# PIC32MX695F512L register map
Registers are 32-bit, access not given, reset 0x0 unless marked. A register's access mark holds for its fields unless they carry their own. Offsets are from the block's base; [hi:lo] are bit positions; {n}, {i} and the like mark numbered series; 'fields as' and 'values as' point back to an identical list.

## INT — INT peripheral
Base 0xBF881000
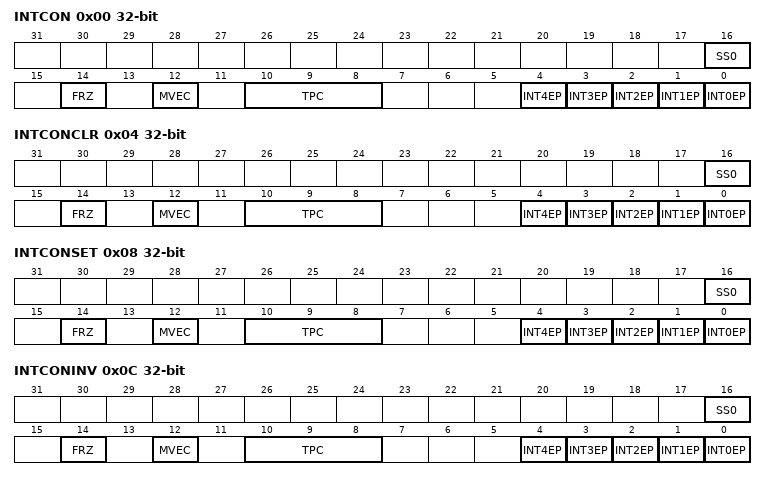
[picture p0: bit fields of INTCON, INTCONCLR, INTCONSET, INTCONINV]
0x00 INTCON
  [16] SS0, [14] FRZ, [12] MVEC, [10:8] TPC, [n] INT{n}EP (n=0..4)
0x04 INTCONCLR
  [16] SS0, [14] FRZ, [12] MVEC, [10:8] TPC, [n] INT{n}EP (n=0..4)
0x08 INTCONSET
  [16] SS0, [14] FRZ, [12] MVEC, [10:8] TPC, [n] INT{n}EP (n=0..4)
0x0C INTCONINV
  [16] SS0, [14] FRZ, [12] MVEC, [10:8] TPC, [n] INT{n}EP (n=0..4)
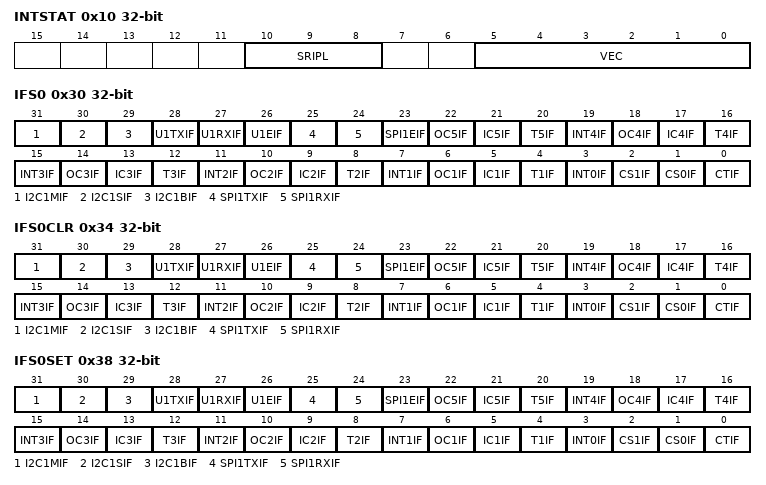
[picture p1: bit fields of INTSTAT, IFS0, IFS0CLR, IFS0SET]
0x10 INTSTAT
  [10:8] SRIPL, [5:0] VEC
0x20 IPTMR
0x24 IPTMRCLR
  [31:0] IPTMR
0x28 IPTMRSET
  [31:0] IPTMR
0x2C IPTMRINV
  [31:0] IPTMR
0x30 IFS0
  [31] I2C1MIF, [30] I2C1SIF, [29] I2C1BIF, [28] U1TXIF, [27] U1RXIF, [26] U1EIF, [25] SPI1TXIF, [24] SPI1RXIF, [23] SPI1EIF, [4n+2] OC{n}IF (n=1..5), [4n+1] IC{n}IF (n=1..5), [4n] T{n}IF (n=1..5), [4n+3] INT{n}IF (n=0..4), [2] CS1IF, [1] CS0IF, [0] CTIF
0x34 IFS0CLR
  fields as IFS0
0x38 IFS0SET
  fields as IFS0
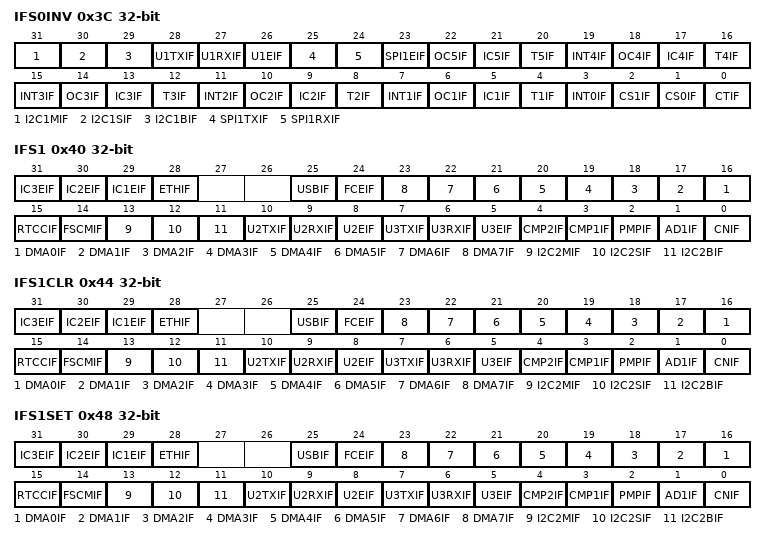
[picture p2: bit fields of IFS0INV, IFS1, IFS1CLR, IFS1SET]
0x3C IFS0INV
  fields as IFS0
0x40 IFS1
  [31] IC3EIF, [30] IC2EIF, [29] IC1EIF, [28] ETHIF, [25] USBIF, [24] FCEIF, [n+16] DMA{n}IF (n=0..7), [15] RTCCIF, [14] FSCMIF, [13] I2C2MIF, [12] I2C2SIF, [11] I2C2BIF, [10] U2TXIF, [9] U2RXIF, [8] U2EIF, [7] U3TXIF, [6] U3RXIF, [5] U3EIF, [4] CMP2IF, [3] CMP1IF, [2] PMPIF, [1] AD1IF, [0] CNIF
0x44 IFS1CLR
  fields as IFS1
0x48 IFS1SET
  fields as IFS1
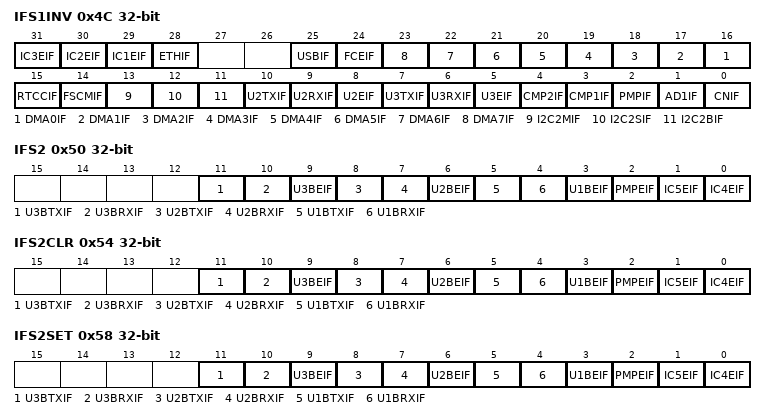
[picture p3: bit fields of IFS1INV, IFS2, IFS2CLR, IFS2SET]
0x4C IFS1INV
  fields as IFS1
0x50 IFS2
  [11] U3BTXIF, [10] U3BRXIF, [9] U3BEIF, [8] U2BTXIF, [7] U2BRXIF, [6] U2BEIF, [5] U1BTXIF, [4] U1BRXIF, [3] U1BEIF, [2] PMPEIF, [1] IC5EIF, [0] IC4EIF
0x54 IFS2CLR
  fields as IFS2
0x58 IFS2SET
  fields as IFS2
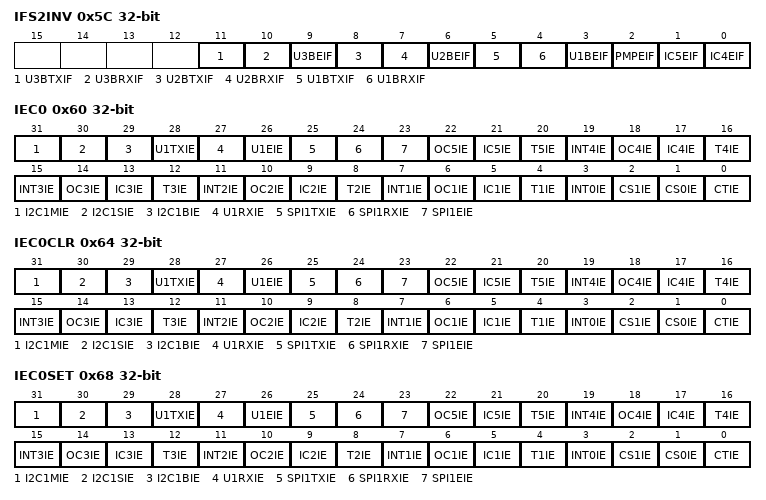
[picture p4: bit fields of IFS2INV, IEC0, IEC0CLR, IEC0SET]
0x5C IFS2INV
  fields as IFS2
0x60 IEC0
  [31] I2C1MIE, [30] I2C1SIE, [29] I2C1BIE, [28] U1TXIE, [27] U1RXIE, [26] U1EIE, [25] SPI1TXIE, [24] SPI1RXIE, [23] SPI1EIE, [4n+2] OC{n}IE (n=1..5), [4n+1] IC{n}IE (n=1..5), [4n] T{n}IE (n=1..5), [4n+3] INT{n}IE (n=0..4), [2] CS1IE, [1] CS0IE, [0] CTIE
0x64 IEC0CLR
  fields as IEC0
0x68 IEC0SET
  fields as IEC0
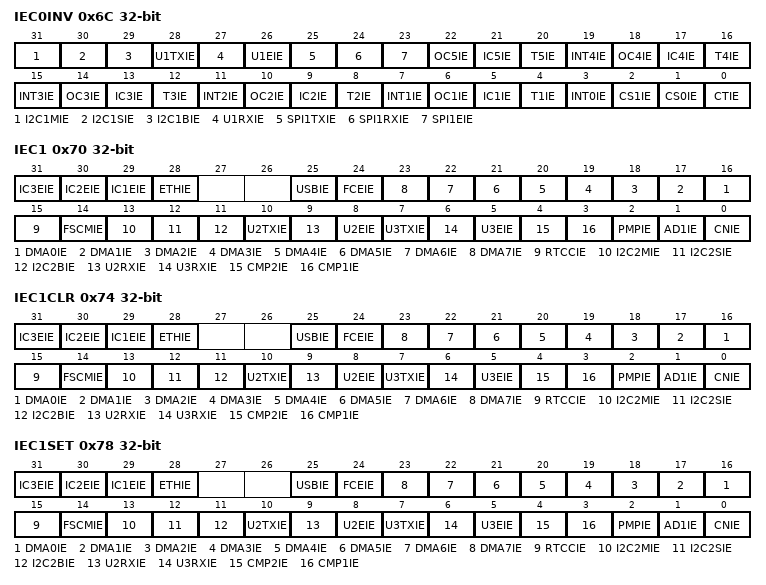
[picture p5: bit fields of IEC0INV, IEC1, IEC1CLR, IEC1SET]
0x6C IEC0INV
  fields as IEC0
0x70 IEC1
  [31] IC3EIE, [30] IC2EIE, [29] IC1EIE, [28] ETHIE, [25] USBIE, [24] FCEIE, [n+16] DMA{n}IE (n=0..7), [15] RTCCIE, [14] FSCMIE, [13] I2C2MIE, [12] I2C2SIE, [11] I2C2BIE, [10] U2TXIE, [9] U2RXIE, [8] U2EIE, [7] U3TXIE, [6] U3RXIE, [5] U3EIE, [4] CMP2IE, [3] CMP1IE, [2] PMPIE, [1] AD1IE, [0] CNIE
0x74 IEC1CLR
  fields as IEC1
0x78 IEC1SET
  fields as IEC1
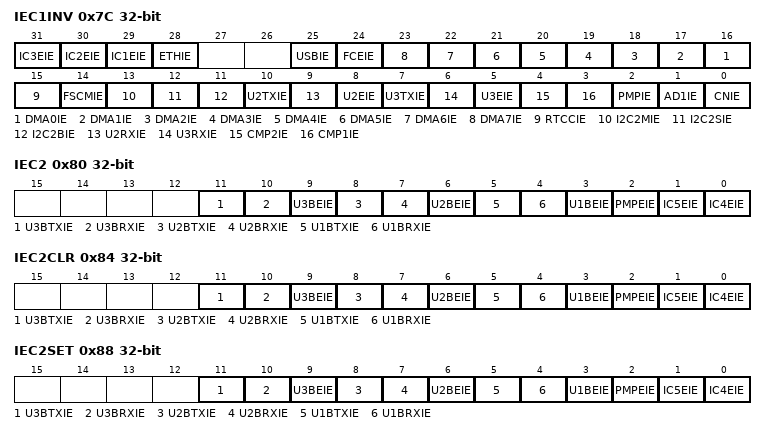
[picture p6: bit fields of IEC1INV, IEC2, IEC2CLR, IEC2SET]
0x7C IEC1INV
  fields as IEC1
0x80 IEC2
  [11] U3BTXIE, [10] U3BRXIE, [9] U3BEIE, [8] U2BTXIE, [7] U2BRXIE, [6] U2BEIE, [5] U1BTXIE, [4] U1BRXIE, [3] U1BEIE, [2] PMPEIE, [1] IC5EIE, [0] IC4EIE
0x84 IEC2CLR
  fields as IEC2
0x88 IEC2SET
  fields as IEC2
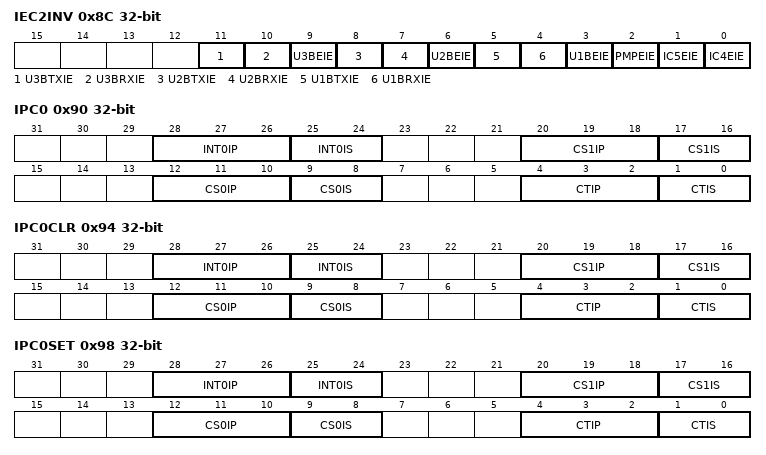
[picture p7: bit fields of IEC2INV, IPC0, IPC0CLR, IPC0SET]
0x8C IEC2INV
  fields as IEC2
0x90 IPC0
  [28:26] INT0IP, [25:24] INT0IS, [20:18] CS1IP, [17:16] CS1IS, [12:10] CS0IP, [9:8] CS0IS, [4:2] CTIP, [1:0] CTIS
0x94 IPC0CLR
  fields as IPC0
0x98 IPC0SET
  fields as IPC0
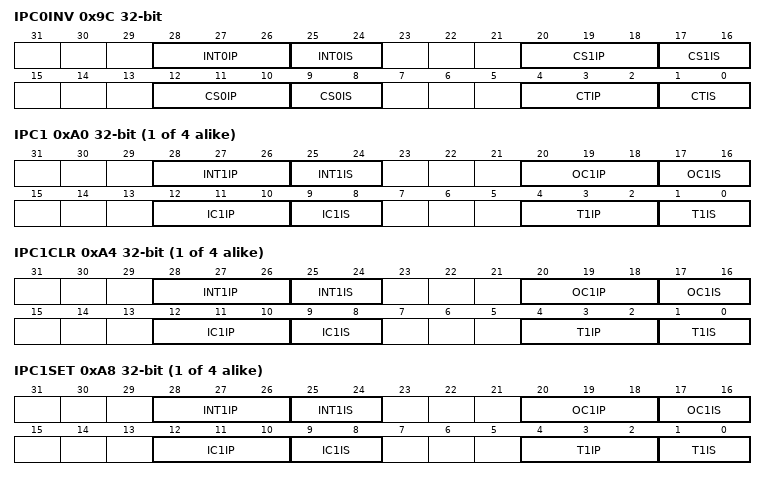
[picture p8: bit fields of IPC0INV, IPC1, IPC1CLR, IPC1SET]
0x9C IPC0INV
  fields as IPC0
{0x90+0x10*i} IPC{i} (i=1..4)
  [28:26] INT{i}IP, [25:24] INT{i}IS, [20:18] OC{i}IP, [17:16] OC{i}IS, [12:10] IC{i}IP, [9:8] IC{i}IS, [4:2] T{i}IP, [1:0] T{i}IS
{0x94+0x10*i} IPC{i}CLR (i=1..4)
  fields as IPC1
{0x98+0x10*i} IPC{i}SET (i=1..4)
  fields as IPC1
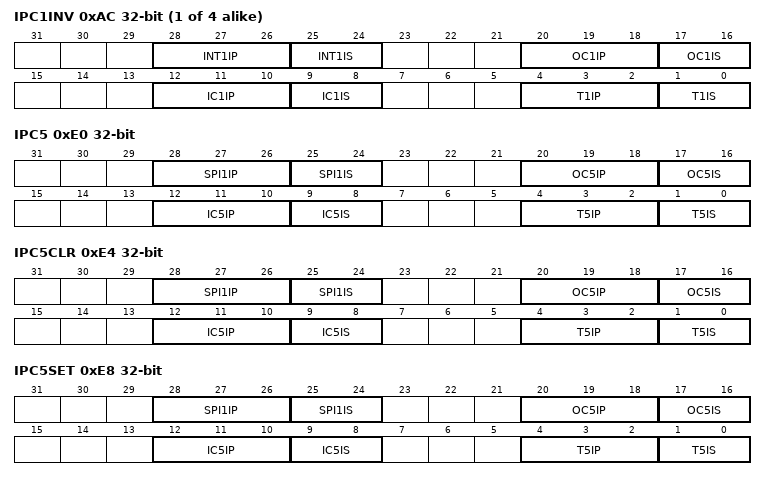
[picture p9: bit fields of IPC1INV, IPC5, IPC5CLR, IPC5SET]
{0x9C+0x10*i} IPC{i}INV (i=1..4)
  fields as IPC1
0xE0 IPC5
  [28:26] SPI1IP, [25:24] SPI1IS, [20:18] OC5IP, [17:16] OC5IS, [12:10] IC5IP, [9:8] IC5IS, [4:2] T5IP, [1:0] T5IS
0xE4 IPC5CLR
  fields as IPC5
0xE8 IPC5SET
  fields as IPC5
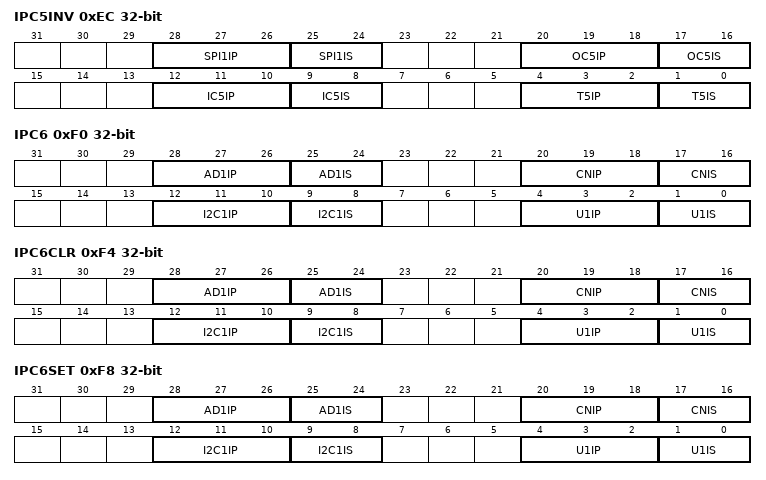
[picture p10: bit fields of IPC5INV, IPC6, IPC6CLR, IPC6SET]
0xEC IPC5INV
  fields as IPC5
0xF0 IPC6
  [28:26] AD1IP, [25:24] AD1IS, [20:18] CNIP, [17:16] CNIS, [12:10] I2C1IP, [9:8] I2C1IS, [4:2] U1IP, [1:0] U1IS
0xF4 IPC6CLR
  fields as IPC6
0xF8 IPC6SET
  fields as IPC6
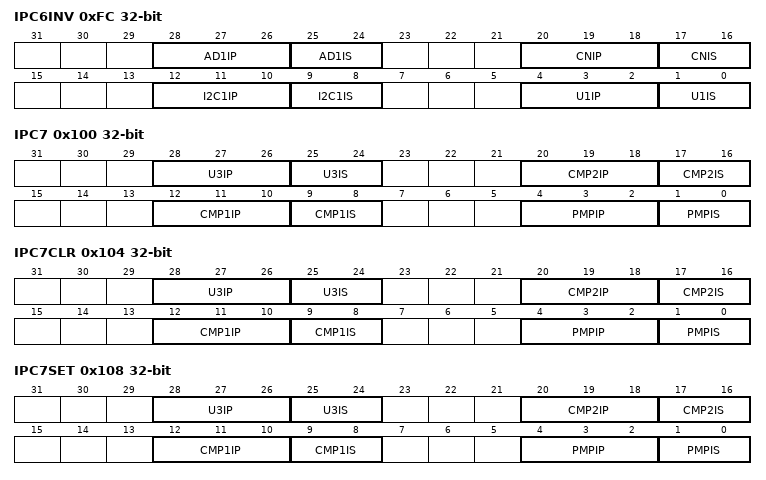
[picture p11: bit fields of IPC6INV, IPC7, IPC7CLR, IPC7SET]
0xFC IPC6INV
  fields as IPC6
0x100 IPC7
  [28:26] U3IP, [25:24] U3IS, [20:18] CMP2IP, [17:16] CMP2IS, [12:10] CMP1IP, [9:8] CMP1IS, [4:2] PMPIP, [1:0] PMPIS
0x104 IPC7CLR
  fields as IPC7
0x108 IPC7SET
  fields as IPC7
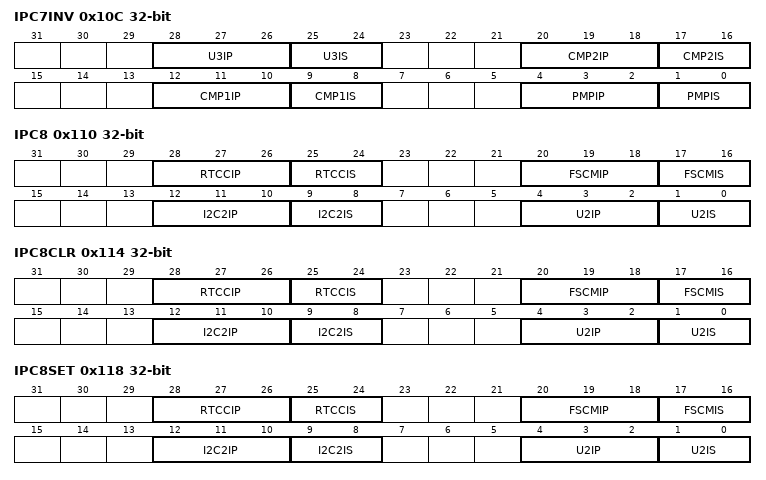
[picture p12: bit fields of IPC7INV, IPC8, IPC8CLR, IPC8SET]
0x10C IPC7INV
  fields as IPC7
0x110 IPC8
  [28:26] RTCCIP, [25:24] RTCCIS, [20:18] FSCMIP, [17:16] FSCMIS, [12:10] I2C2IP, [9:8] I2C2IS, [4:2] U2IP, [1:0] U2IS
0x114 IPC8CLR
  fields as IPC8
0x118 IPC8SET
  fields as IPC8
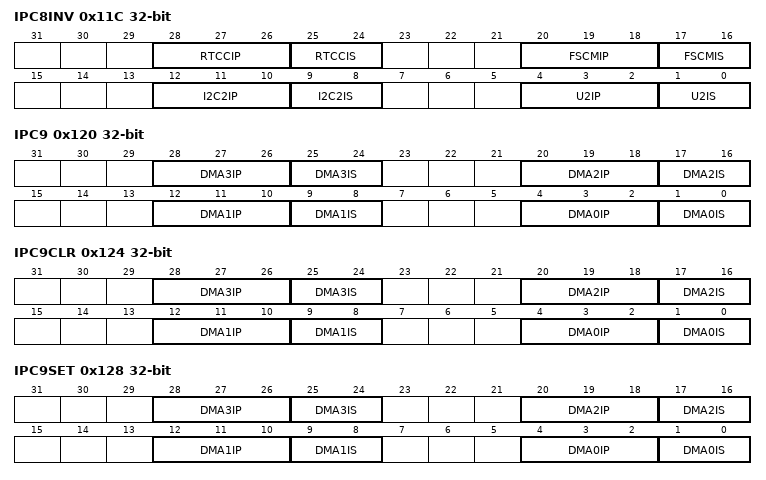
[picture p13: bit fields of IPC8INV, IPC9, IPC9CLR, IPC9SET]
0x11C IPC8INV
  fields as IPC8
0x120 IPC9
  [8n+4:8n+2] DMA{n}IP (n=0..3), [8n+1:8n] DMA{n}IS (n=0..3)
0x124 IPC9CLR
  [8n+4:8n+2] DMA{n}IP (n=0..3), [8n+1:8n] DMA{n}IS (n=0..3)
0x128 IPC9SET
  [8n+4:8n+2] DMA{n}IP (n=0..3), [8n+1:8n] DMA{n}IS (n=0..3)
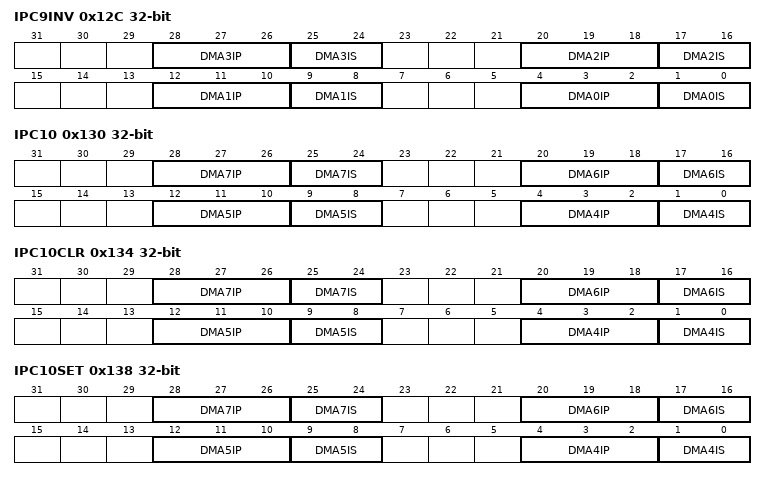
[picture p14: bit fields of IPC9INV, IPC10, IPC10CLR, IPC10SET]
0x12C IPC9INV
  [8n+4:8n+2] DMA{n}IP (n=0..3), [8n+1:8n] DMA{n}IS (n=0..3)
0x130 IPC10
  [8n-28:8n-30] DMA{n}IP (n=4..7), [8n-31:8n-32] DMA{n}IS (n=4..7)
0x134 IPC10CLR
  [8n-28:8n-30] DMA{n}IP (n=4..7), [8n-31:8n-32] DMA{n}IS (n=4..7)
0x138 IPC10SET
  [8n-28:8n-30] DMA{n}IP (n=4..7), [8n-31:8n-32] DMA{n}IS (n=4..7)
0x13C IPC10INV
  [8n-28:8n-30] DMA{n}IP (n=4..7), [8n-31:8n-32] DMA{n}IS (n=4..7)
0x140 IPC11
  [12:10] USBIP, [9:8] USBIS, [4:2] FCEIP, [1:0] FCEIS
0x144 IPC11CLR
  [12:10] USBIP, [9:8] USBIS, [4:2] FCEIP, [1:0] FCEIS
0x148 IPC11SET
  [12:10] USBIP, [9:8] USBIS, [4:2] FCEIP, [1:0] FCEIS
0x14C IPC11INV
  [12:10] USBIP, [9:8] USBIS, [4:2] FCEIP, [1:0] FCEIS
0x150 IPC12
  [28:26] U5IP, [25:24] U5IS, [20:18] U6IP, [17:16] U6IS, [12:10] U4IP, [9:8] U4IS, [4:2] ETHIP, [1:0] ETHIS
0x154 IPC12CLR
  fields as IPC12
0x158 IPC12SET
  fields as IPC12
0x15C IPC12INV
  fields as IPC12
